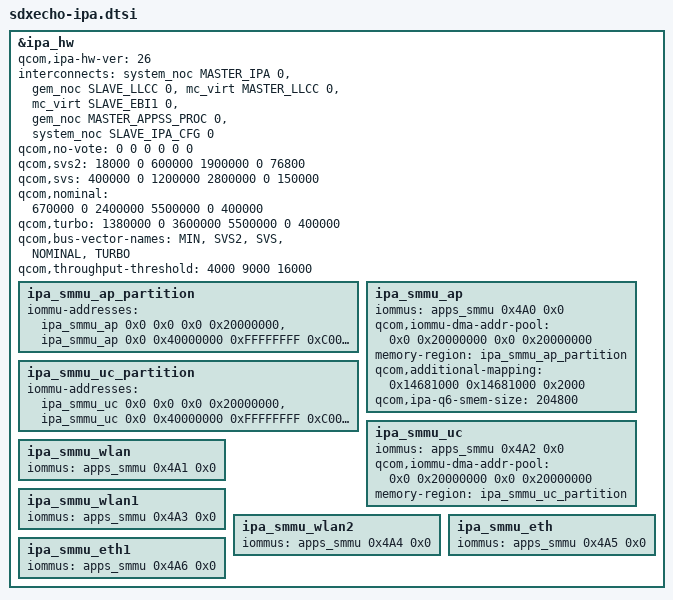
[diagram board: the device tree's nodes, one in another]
// SPDX-License-Identifier: BSD-3-Clause
/*
 * Copyright (c) Qualcomm Technologies, Inc. and/or its subsidiaries.
 */

#include <dt-bindings/interrupt-controller/arm-gic.h>
#include <dt-bindings/mailbox/qcom-ipcc.h>
#include <dt-bindings/mailbox/qcom-ipcc-sdxecho.h>
#include <dt-bindings/interconnect/qcom,sdxecho.h>
#include <dt-bindings/clock/qcom,sdxecho-gcc.h>
#include <dt-bindings/clock/qcom,rpmh.h>
#include "ipa.dtsi"

&ipa_hw{
	qcom,ipa-hw-ver = <26>; /* IPA core version = IPAv7.0 */

	interconnects = <&system_noc MASTER_IPA 0 &gem_noc SLAVE_LLCC 0>,
	<&mc_virt MASTER_LLCC 0 &mc_virt SLAVE_EBI1 0>,
	<&gem_noc MASTER_APPSS_PROC 0 &system_noc SLAVE_IPA_CFG 0>;

	interconnect-names = "ipa_to_llcc", "llcc_to_ebi1", "appss_to_ipa";
	/* No vote */
	qcom,no-vote =
	<0 0 0 0 0 0>;

	/* SVS2 */
	qcom,svs2 =
	<18000 0 600000 1900000 0 76800>;

	/* SVS */
	qcom,svs =
	<400000 0 1200000 2800000 0 150000>;

	/* NOMINAL */
	qcom,nominal =
	<670000 0 2400000 5500000 0 400000>;

	/* TURBO */
	qcom,turbo =
	<1380000 0 3600000 5500000 0 400000>;

	qcom,bus-vector-names = "MIN", "SVS2", "SVS", "NOMINAL",
		"TURBO";
	qcom,throughput-threshold = <4000 9000 16000>;

	ipa_smmu_ap_partition: ipa_smmu_ap_partition {
		iommu-addresses = <&ipa_smmu_ap 0x0 0x0 0x0 0x20000000>,
			<&ipa_smmu_ap 0x0 0x40000000 0xFFFFFFFF 0xC0000000>;
	};

	ipa_smmu_uc_partition: ipa_smmu_uc_partition {
		iommu-addresses = <&ipa_smmu_uc 0x0 0x0 0x0 0x20000000>,
			<&ipa_smmu_uc 0x0 0x40000000 0xFFFFFFFF 0xC0000000>;
	};

	ipa_smmu_ap: ipa_smmu_ap {
		iommus = <&apps_smmu 0x4A0 0x0>;
		qcom,iommu-dma-addr-pool = <0x0 0x20000000 0x0 0x20000000>;
		memory-region = <&ipa_smmu_ap_partition>;
		qcom,additional-mapping =
			/* modem tables in IMEM */
			<0x14681000 0x14681000 0x2000>;
		qcom,ipa-q6-smem-size = <204800>;
	};

	ipa_smmu_uc: ipa_smmu_uc {
		iommus = <&apps_smmu 0x4A2 0x0>;
		qcom,iommu-dma-addr-pool = <0x0 0x20000000 0x0 0x20000000>;
		memory-region = <&ipa_smmu_uc_partition>;
	};

	ipa_smmu_wlan: ipa_smmu_wlan {
		iommus = <&apps_smmu 0x4A1 0x0>;
	};

	ipa_smmu_wlan1: ipa_smmu_wlan1 {
		iommus = <&apps_smmu 0x4A3 0x0>;
	};

	ipa_smmu_wlan2: ipa_smmu_wlan2 {
		iommus = <&apps_smmu 0x4A4 0x0>;
	};

	ipa_smmu_eth: ipa_smmu_eth {
		iommus = <&apps_smmu 0x4A5 0x0>;
	};

	ipa_smmu_eth1: ipa_smmu_eth1 {
		iommus = <&apps_smmu 0x4A6 0x0>;
	};
};

